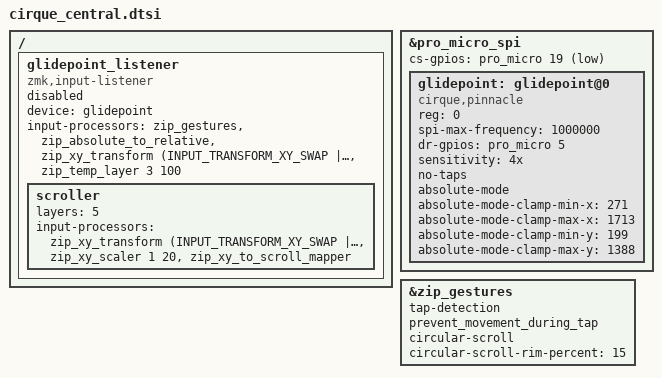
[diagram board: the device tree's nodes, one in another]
#include <input/processors.dtsi>
#include <dt-bindings/zmk/input_transform.h>
#include <behaviors/input_processor_gestures.dtsi>
#include <behaviors/input_processor_absolute_to_relative.dtsi>

&pro_micro_spi {
    status = "okay";
    cs-gpios = <&pro_micro 19 GPIO_ACTIVE_LOW>;

    glidepoint: glidepoint@0 {
        compatible = "cirque,pinnacle";
        reg = <0>;
        spi-max-frequency = <1000000>;
        status = "okay";
        dr-gpios = <&pro_micro 5 (GPIO_ACTIVE_HIGH)>;

        sensitivity = "4x";
        // sleep;
        no-taps;
        absolute-mode;

        absolute-mode-clamp-min-x=<271>;
        absolute-mode-clamp-max-x=<1713>;
        absolute-mode-clamp-min-y=<199>;
        absolute-mode-clamp-max-y=<1388>;
    };
};


&zip_gestures {
    tap-detection;
    prevent_movement_during_tap;

    circular-scroll;
    circular-scroll-rim-percent=<15>;
};

/ {
    glidepoint_listener: glidepoint_listener {
        compatible = "zmk,input-listener";
        status = "disabled";
        device = <&glidepoint>;
        input-processors = <
            &zip_gestures
            &zip_absolute_to_relative
            &zip_xy_transform (INPUT_TRANSFORM_XY_SWAP | INPUT_TRANSFORM_Y_INVERT)
            &zip_temp_layer 3 100
        >;
        scroller {
            layers = <5>;
            input-processors = <
                &zip_xy_transform (INPUT_TRANSFORM_XY_SWAP | INPUT_TRANSFORM_X_INVERT)
                &zip_xy_scaler 1 20
                &zip_xy_to_scroll_mapper
            >;
        };
    };
};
